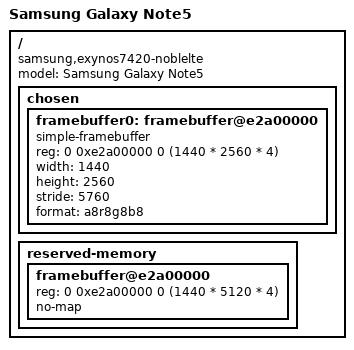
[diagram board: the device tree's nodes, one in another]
#include "exynos7420-zero-common.dtsi"

/ {
	model = "Samsung Galaxy Note5";
	compatible = "samsung,exynos7420-noblelte", "samsung,exynos7420", \
			"samsung,exynos7";

	chosen {
        	#address-cells = <2>;
        	#size-cells = <2>;
        	ranges;

                framebuffer0: framebuffer@e2a00000 {
			compatible = "simple-framebuffer";
			reg = <0 0xe2a00000 0 (1440 * 2560 * 4)>;
			width = <1440>;
			height = <2560>;
			stride = <5760>;
			format = "a8r8g8b8";
		};
	};

       reserved-memory {
		#address-cells = <2>;
		#size-cells = <2>;
        	ranges;

        	framebuffer@e2a00000 {
                	reg = <0 0xe2a00000 0 (1440 * 5120 * 4)>;
                	no-map;
		};
	};
};
